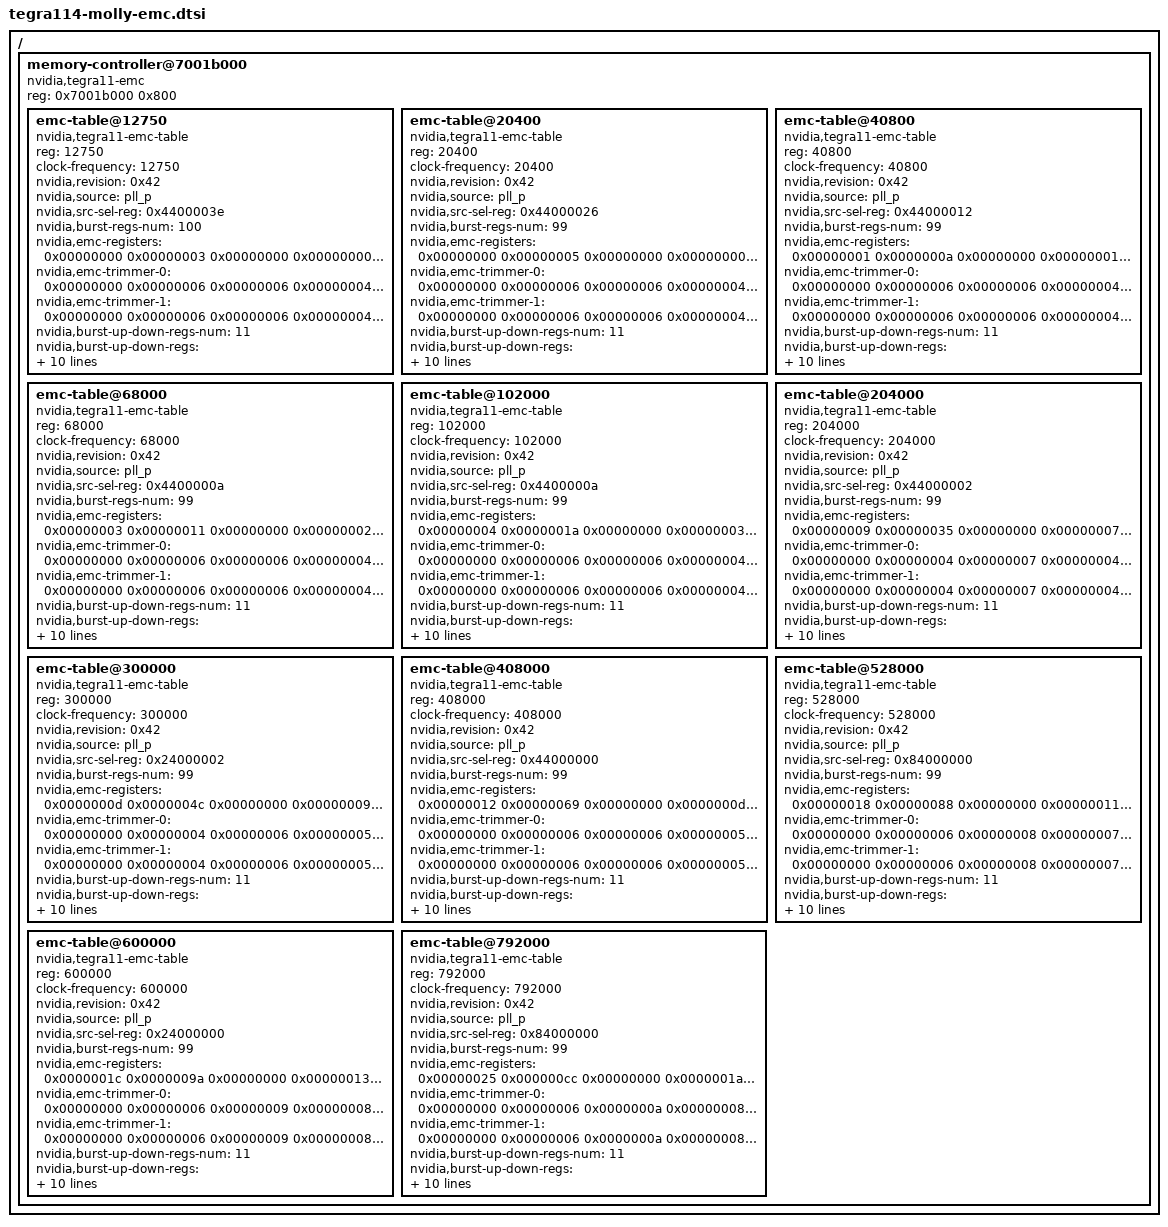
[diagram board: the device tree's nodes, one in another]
/ {
memory-controller@7001b000 {
	    compatible = "nvidia,tegra11-emc";
	    reg = <0x7001b000 0x800>;
	    #address-cells = <1>;
	    #size-cells = <0>;
	    emc-table@12750 {
		    reg = <12750>;
		    compatible = "nvidia,tegra11-emc-table";
		    clock-frequency = <12750>;
		    nvidia,revision = <0x42>;
		    nvidia,source = "pll_p";
		    nvidia,src-sel-reg = <0x4400003e>;
		    nvidia,burst-regs-num = <100>;
		    nvidia,emc-registers = <
			    0x00000000
			    0x00000003
			    0x00000000
			    0x00000000
		    	0x00000000
		    	0x00000004
		    	0x0000000a
		    	0x00000003
		    	0x0000000b
		    	0x00000000
		    	0x00000000
		    	0x00000003
		    	0x00000001
		    	0x00000000
		    	0x00000005
		    	0x0000000f
		    	0x00000006
		    	0x00010000
			    0x00000000
			    0x00000004
			    0x0000000f
			    0x00000060
			    0x00000000
			    0x00000018
			    0x00000002
			    0x00000002
		    	0x00000001
			    0x00000000
		    	0x00000007
		    	0x0000000f
			    0x00000005
			    0x00000005
			    0x00000004
			    0x00000004
			    0x00000004
		    	0x00000004
			    0x00000000
			    0x00000004
		    	0x00000005
		    	0x00000064
		    	0x00000005
		    	0x00000020
		    	0x00000000
		    	0x0000aa88
		    	0x002c00a0
		    	0x00008000
		    	0x00064000
		    	0x00064000
		    	0x00064000
			    0x00064000
			    0x00000000
		    	0x00000000
		    	0x00000000
			    0x00000000
			    0x00000000
			    0x00000000
			    0x00000000
			    0x00000000
		    	0x001112a0
		    	0x00000000
		    	0x0000a11c
			    0x00000000
                0x77ffc085
			    0x81f1f108
		    	0x03037504
			    0x0000003f
			    0x0000003f
			    0x00000007
			    0x02000000
			    0x00000802
			    0x00000000
			    0x00000042
			    0x000c000c
			    0x000c000c
			    0x00000000
			    0x00000000
			    0x00000000
			    0x00000000
			    0x800001c5
		    	0x1f7df7df
		    	0x0000001f
		    	0x40040001
		    	0x8000003f
		    	0x00000001
		    	0x00000001
			    0x00000002
			    0x00000000
			    0x00000001
			    0x00000001
			    0x00000002
			    0x00000008
			    0x00000002
			    0x00000001
			    0x00000003
			    0x00000006
		    	0x06030102
			    0x000a0402
			    0x77e30303
			    0x001f0000
		>;
		nvidia,emc-trimmer-0 = <
			0x00000000
			0x00000006
			0x00000006
			0x00000004
			0x00000004
			0x00064000
			0x00000009
			0x00000000
			0x0000000d
			0x00249249
			0x20820800
			0x0007c000
			0xa0f10f0f
			0x00000000
			0x00000a0a
			0x00000000
			0x00000000
			0x00000000
			0x00064000
			0x00064000
			0x00064000
			0x0007c000
			0x0007c000
			0x0007c000
			0x00000000
			0x00000000
			0x00000000
			0x00000000
			0x00000000
			0x00000000
		>;
		nvidia,emc-trimmer-1 = <
			0x00000000
			0x00000006
			0x00000006
			0x00000004
			0x00000004
			0x00064000
			0x00000009
			0x00000000
			0x0000000d
			0x00249249
			0x20820800
			0x0007c000
			0xa8f10f0f
			0x00000000
			0x00000b0b
			0x00000000
			0x00000000
			0x00000000
			0x00064000
			0x00064000
			0x00064000
			0x0007c000
			0x0007c000
			0x0007c000
			0x00000000
			0x00000000
			0x00000000
			0x00000000
			0x00000000
			0x00000000
		>;
		nvidia,burst-up-down-regs-num = <11>;
		nvidia,burst-up-down-regs = <
			0x00000007
			0x00ff00ff
			0x00ff00ff
			0x00ff00ff
			0x000000ff
			0x00ff00ff
			0x00ff00ff
			0x000000ff
			0x00ff00ff
			0x00ff00ff
			0x00ff00ff
		>;
		nvidia,emc-zcal-cnt-long = <0x00000042>;
		nvidia,emc-acal-interval = <0x001fffff>;
		nvidia,emc-mode-cfg = <0x7324000e>;
		nvidia,emc-mode-reset = <0x80001221>;
		nvidia,emc-mode-1 = <0x80100003>;
		nvidia,emc-mode-2 = <0x80200008>;
		nvidia,emc-mode-4 = <0x00000000>;
		nvidia,emc-min-mv = <900>;
		nvidia,emc-clock-latency-change = <57820>;
        };
	emc-table@20400 {
		reg = <20400>;
		compatible = "nvidia,tegra11-emc-table";
		clock-frequency = <20400>;
		nvidia,revision = <0x42>;
		nvidia,source = "pll_p";
		nvidia,src-sel-reg = <0x44000026>;
		nvidia,burst-regs-num = <99>;
		nvidia,emc-registers = <
			0x00000000
			0x00000005
			0x00000000
			0x00000000
			0x00000000
			0x00000004
			0x0000000a
			0x00000003
			0x0000000b
			0x00000000
			0x00000000
			0x00000003
			0x00000001
			0x00000000
			0x00000005
			0x0000000f
			0x00000006
			0x00010000
			0x00000000
			0x00000004
			0x0000000f
			0x0000009a
			0x00000000
			0x00000026
			0x00000002
			0x00000002
			0x00000001
			0x00000000
			0x00000007
			0x0000000f
			0x00000006
			0x00000006
			0x00000004
			0x00000004
			0x00000004
			0x00000004
			0x00000000
			0x00000004
			0x00000005
			0x000000a0
			0x00000005
			0x00000020
			0x00000000
			0x0000aa88
			0x002c00a0
			0x00008000
			0x00064000
			0x00064000
			0x00064000
			0x00064000
			0x00000000
			0x00000000
			0x00000000
			0x00000000
			0x00000000
			0x00000000
			0x00000000
			0x00000000
			0x001112a0
			0x00000000
			0x0000a11c
			0x00000000
			0x77ffc085
			0x81f1f108
			0x03037504
			0x0000003f
			0x0000003f
			0x0000000b
			0x02000000
			0x00000802
			0x00000000
			0x00000042
			0x000c000c
			0x000c000c
			0x00000000
			0x00000000
			0x00000000
			0x00000000
			0x8000023a
			0x1f7df7df
			0x0000001f
			0x40020001
			0x80000046
			0x00000001
			0x00000001
			0x00000002
			0x00000000
			0x00000001
			0x00000001
			0x00000002
			0x00000008
			0x00000002
			0x00000001
			0x00000003
			0x00000006
			0x06030102
			0x000a0402
			0x76230303
			0x001f0000
		>;
		nvidia,emc-trimmer-0 = <
			0x00000000
			0x00000006
			0x00000006
			0x00000004
			0x00000004
			0x00064000
			0x00000009
			0x00000000
			0x0000000d
			0x00249249
			0x20820800
			0x0007c000
			0xa0f10f0f
			0x00000000
			0x00000a0a
			0x00000000
			0x00000000
			0x00000000
			0x00064000
			0x00064000
			0x00064000
			0x0007c000
			0x0007c000
			0x0007c000
			0x00000000
			0x00000000
			0x00000000
			0x00000000
			0x00000000
			0x00000000
		>;
		nvidia,emc-trimmer-1 = <
			0x00000000
			0x00000006
			0x00000006
			0x00000004
			0x00000004
			0x00064000
			0x00000009
			0x00000000
			0x0000000d
			0x00249249
			0x20820800
			0x0007c000
			0xa8f10f0f
			0x00000000
			0x00000b0b
			0x00000000
			0x00000000
			0x00000000
			0x00064000
			0x00064000
			0x00064000
			0x0007c000
			0x0007c000
			0x0007c000
			0x00000000
			0x00000000
			0x00000000
			0x00000000
			0x00000000
			0x00000000
		>;
		nvidia,burst-up-down-regs-num = <11>;
		nvidia,burst-up-down-regs = <
			0x0000000a
			0x00ff00ff
			0x00ff00ff
			0x00ff00ff
			0x000000ff
			0x00ff00ff
			0x00ff00ff
			0x000000ff
			0x00ff00ff
			0x00ff00ff
			0x00ff00ff
		>;
		nvidia,emc-zcal-cnt-long = <0x00000042>;
		nvidia,emc-acal-interval = <0x001fffff>;
		nvidia,emc-mode-cfg = <0x7324000e>;
		nvidia,emc-mode-reset = <0x80001221>;
		nvidia,emc-mode-1 = <0x80100003>;
		nvidia,emc-mode-2 = <0x80200008>;
		nvidia,emc-mode-4 = <0x00000000>;
		nvidia,emc-min-mv = <900>;
		nvidia,emc-clock-latency-change = <35610>;
        };

	emc-table@40800 {
		reg = <40800>;
		compatible = "nvidia,tegra11-emc-table";
		clock-frequency = <40800>;
		nvidia,revision = <0x42>;
		nvidia,source = "pll_p";
		nvidia,src-sel-reg = <0x44000012>;
		nvidia,burst-regs-num = <99>;
		nvidia,emc-registers = <
			0x00000001
			0x0000000a
			0x00000000
			0x00000001
			0x00000000
			0x00000004
			0x0000000a
			0x00000003
			0x0000000b
			0x00000000
			0x00000000
			0x00000003
			0x00000001
			0x00000000
			0x00000005
			0x0000000f
			0x00000006
			0x00010000
			0x00000000
			0x00000004
			0x0000000f
			0x00000134
			0x00000000
			0x0000004d
			0x00000002
			0x00000002
			0x00000001
			0x00000000
			0x00000008
			0x0000000f
			0x0000000c
			0x0000000c
			0x00000004
			0x00000004
			0x00000004
			0x00000004
			0x00000000
			0x00000004
			0x00000005
			0x0000013f
			0x00000005
			0x00000020
			0x00000000
			0x0000aa88
			0x002c00a0
			0x00008000
			0x00064000
			0x00064000
			0x00064000
			0x00064000
			0x00000000
			0x00000000
			0x00000000
			0x00000000
			0x00000000
			0x00000000
			0x00000000
			0x00000000
			0x001112a0
			0x00000000
			0x0000a11c
			0x00000000
			0x77ffc085
			0x81f1f108
			0x03037504
			0x0000003f
			0x0000003f
			0x00000015
			0x02000000
			0x00000802
			0x00000000
			0x00000042
			0x000c000c
			0x000c000c
			0x00000000
			0x00000000
			0x00000000
			0x00000000
			0x80000370
			0x1f7df7df
			0x0000001f
			0xa0000001
			0x8000005b
			0x00000001
			0x00000001
			0x00000002
			0x00000000
			0x00000001
			0x00000001
			0x00000002
			0x00000008
			0x00000002
			0x00000001
			0x00000003
			0x00000006
			0x06030102
			0x000a0402
			0x74a30303
			0x001f0000
		>;
		nvidia,emc-trimmer-0 = <
			0x00000000
			0x00000006
			0x00000006
			0x00000004
			0x00000004
			0x00064000
			0x00000009
			0x00000000
			0x0000000d
			0x00249249
			0x20820800
			0x0007c000
			0xa0f10f0f
			0x00000000
			0x00000a0a
			0x00000000
			0x00000000
			0x00000000
			0x00064000
			0x00064000
			0x00064000
			0x0007c000
			0x0007c000
			0x0007c000
			0x00000000
			0x00000000
			0x00000000
			0x00000000
			0x00000000
			0x00000000
		>;
		nvidia,emc-trimmer-1 = <
			0x00000000
			0x00000006
			0x00000006
			0x00000004
			0x00000004
			0x00064000
			0x00000009
			0x00000000
			0x0000000d
			0x00249249
			0x20820800
			0x0007c000
			0xa8f10f0f
			0x00000000
			0x00000b0b
			0x00000000
			0x00000000
			0x00000000
			0x00064000
			0x00064000
			0x00064000
			0x0007c000
			0x0007c000
			0x0007c000
			0x00000000
			0x00000000
			0x00000000
			0x00000000
			0x00000000
			0x00000000
		>;
		nvidia,burst-up-down-regs-num = <11>;
		nvidia,burst-up-down-regs = <
			0x00000015
			0x00b000b0
			0x00b000c4
			0x00d700eb
			0x000000eb
			0x00eb00eb
			0x00ff00eb
			0x000000ff
			0x00ff00ff
			0x00ff00ff
			0x00ff00ff
		>;
		nvidia,emc-zcal-cnt-long = <0x00000042>;
		nvidia,emc-acal-interval = <0x001fffff>;
		nvidia,emc-mode-cfg = <0x7324000e>;
		nvidia,emc-mode-reset = <0x80001221>;
		nvidia,emc-mode-1 = <0x80100003>;
		nvidia,emc-mode-2 = <0x80200008>;
		nvidia,emc-mode-4 = <0x00000000>;
		nvidia,emc-min-mv = <900>;
		nvidia,emc-clock-latency-change = <20850>;
        };

	emc-table@68000 {
		reg = <68000>;
		compatible = "nvidia,tegra11-emc-table";
		clock-frequency = <68000>;
		nvidia,revision = <0x42>;
		nvidia,source = "pll_p";
		nvidia,src-sel-reg = <0x4400000a>;
		nvidia,burst-regs-num = <99>;
		nvidia,emc-registers = <
			0x00000003
			0x00000011
			0x00000000
			0x00000002
			0x00000000
			0x00000004
			0x0000000a
			0x00000003
			0x0000000b
			0x00000000
			0x00000000
			0x00000003
			0x00000001
			0x00000000
			0x00000005
			0x0000000f
			0x00000006
			0x00010000
			0x00000000
			0x00000004
			0x0000000f
			0x00000202
			0x00000000
			0x00000080
			0x00000002
			0x00000002
			0x00000001
			0x00000000
			0x0000000f
			0x0000000f
			0x00000013
			0x00000013
			0x00000004
			0x00000004
			0x00000004
			0x00000004
			0x00000000
			0x00000004
			0x00000005
			0x00000213
			0x00000005
			0x00000020
			0x00000000
			0x0000aa88
			0x002c00a0
			0x00008000
			0x00064000
			0x00064000
			0x00064000
			0x00064000
			0x00000000
			0x00000000
			0x00000000
			0x00000000
			0x00000000
			0x00000000
			0x00000000
			0x00000000
			0x001112a0
			0x00000000
			0x0000a11c
			0x00000000
			0x77ffc085
			0x81f1f108
			0x03037504
			0x0000003f
			0x0000003f
			0x00000022
			0x02000000
			0x00000802
			0x00000000
			0x00000042
			0x000c000c
			0x000c000c
			0x00000000
			0x00000000
			0x00000000
			0x00000000
			0x8000050e
			0x1f7df7df
			0x0000001f
			0x00000001
			0x80000076
			0x00000001
			0x00000001
			0x00000002
			0x00000000
			0x00000001
			0x00000001
			0x00000002
			0x00000008
			0x00000002
			0x00000001
			0x00000003
			0x00000006
			0x06030102
			0x000a0402
			0x74230403
			0x001f0000
		>;
		nvidia,emc-trimmer-0 = <
			0x00000000
			0x00000006
			0x00000006
			0x00000004
			0x00000004
			0x00064000
			0x00000009
			0x00000000
			0x0000000d
			0x00249249
			0x20820800
			0x0007c000
			0xa0f10f0f
			0x00008000
			0x00000a0a
			0x00000000
			0x00000000
			0x00008000
			0x00064000
			0x00064000
			0x00064000
			0x0007c000
			0x0007c000
			0x0007c000
			0x00000000
			0x00000000
			0x00000000
			0x00000000
			0x00000000
			0x00000000
		>;
		nvidia,emc-trimmer-1 = <
			0x00000000
			0x00000006
			0x00000006
			0x00000004
			0x00000004
			0x00064000
			0x00000009
			0x00000000
			0x0000000d
			0x00249249
			0x20820800
			0x0007c000
			0xa8f10f0f
			0x0000c000
			0x00000b0b
			0x00000000
			0x00000000
			0x0000c000
			0x00064000
			0x00064000
			0x00064000
			0x0007c000
			0x0007c000
			0x0007c000
			0x00000000
			0x00000000
			0x00000000
			0x00000000
			0x00000000
			0x00000000
		>;
		nvidia,burst-up-down-regs-num = <11>;
		nvidia,burst-up-down-regs = <
			0x00000023
			0x00690069
			0x00690075
			0x0081008d
			0x0000008d
			0x008d008d
			0x00bc008d
			0x000000bc
			0x00bc00bc
			0x00ff00ff
			0x00ff00ff
		>;
		nvidia,emc-zcal-cnt-long = <0x00000042>;
		nvidia,emc-acal-interval = <0x001fffff>;
		nvidia,emc-mode-cfg = <0x7324000e>;
		nvidia,emc-mode-reset = <0x80001221>;
		nvidia,emc-mode-1 = <0x80100003>;
		nvidia,emc-mode-2 = <0x80200008>;
		nvidia,emc-mode-4 = <0x00000000>;
		nvidia,emc-min-mv = <900>;
		nvidia,emc-clock-latency-change = <10720>;
        };

	emc-table@102000 {
		reg = <102000>;
		compatible = "nvidia,tegra11-emc-table";
		clock-frequency = <102000>;
		nvidia,revision = <0x42>;
		nvidia,source = "pll_p";
		nvidia,src-sel-reg = <0x4400000a>;
		nvidia,burst-regs-num = <99>;
		nvidia,emc-registers = <
			0x00000004
			0x0000001a
			0x00000000
			0x00000003
			0x00000001
			0x00000004
			0x0000000a
			0x00000003
			0x0000000b
			0x00000001
			0x00000001
			0x00000003
			0x00000001
			0x00000000
			0x00000005
			0x0000000f
			0x00000006
			0x00010000
			0x00000000
			0x00000004
			0x0000000f
			0x00000303
			0x00000000
			0x000000c0
			0x00000002
			0x00000002
			0x00000001
			0x00000000
			0x00000018
			0x0000000f
			0x0000001c
			0x0000001c
			0x00000004
			0x00000004
			0x00000004
			0x00000005
			0x00000000
			0x00000004
			0x00000005
			0x0000031c
			0x00000005
			0x00000020
			0x00000000
			0x0000aa88
			0x002c00a0
			0x00008000
			0x00064000
			0x00064000
			0x00064000
			0x00064000
			0x00000000
			0x00000000
			0x00000000
			0x00000000
			0x00000000
			0x00000000
			0x00000000
			0x00000000
			0x001112a0
			0x00000000
			0x0000a11c
			0x00000000
			0x77ffc085
			0x81f1f108
			0x03037504
			0x0000003f
			0x0000003f
			0x00000033
			0x02000000
			0x00000802
			0x00000000
			0x00000042
			0x000c000c
			0x000c000c
			0x00000000
			0x00000000
			0x00000000
			0x00000000
			0x80000713
			0x1f7df7df
			0x0000001f
			0x08000001
			0x80000098
			0x00000001
			0x00000001
			0x00000003
			0x00000000
			0x00000002
			0x00000001
			0x00000002
			0x00000008
			0x00000002
			0x00000001
			0x00000003
			0x00000006
			0x06030102
			0x000a0403
			0x73c30504
			0x001f0000
		>;
		nvidia,emc-trimmer-0 = <
			0x00000000
			0x00000006
			0x00000006
			0x00000004
			0x00000004
			0x00064000
			0x00000009
			0x00000000
			0x0000000d
			0x00249249
			0x20820800
			0x0007c000
			0xa0f10f0f
			0x00000000
			0x00000a0a
			0x00000000
			0x00000000
			0x00000000
			0x00064000
			0x00064000
			0x00064000
			0x0007c000
			0x0007c000
			0x0007c000
			0x00000000
			0x00000000
			0x00000000
			0x00000000
			0x00000000
			0x00000000
		>;
		nvidia,emc-trimmer-1 = <
			0x00000000
			0x00000006
			0x00000006
			0x00000004
			0x00000004
			0x00064000
			0x00000009
			0x00000000
			0x0000000d
			0x00249249
			0x20820800
			0x0007c000
			0xa8f10f0f
			0x00000000
			0x00000b0b
			0x00000000
			0x00000000
			0x00000000
			0x00064000
			0x00064000
			0x00064000
			0x0007c000
			0x0007c000
			0x0007c000
			0x00000000
			0x00000000
			0x00000000
			0x00000000
			0x00000000
			0x00000000
		>;
		nvidia,burst-up-down-regs-num = <11>;
		nvidia,burst-up-down-regs = <
			0x00000034
			0x00460046
			0x0046004e
			0x0056005e
			0x0000005e
			0x005e005e
			0x007d005e
			0x0000007d
			0x007d007d
			0x00ff00ff
			0x00ff00ff
		>;
		nvidia,emc-zcal-cnt-long = <0x00000042>;
		nvidia,emc-acal-interval = <0x001fffff>;
		nvidia,emc-mode-cfg = <0x7324000e>;
		nvidia,emc-mode-reset = <0x80001221>;
		nvidia,emc-mode-1 = <0x80100003>;
		nvidia,emc-mode-2 = <0x80200008>;
		nvidia,emc-mode-4 = <0x00000000>;
		nvidia,emc-min-mv = <900>;
		nvidia,emc-clock-latency-change = <6890>;
        };

	emc-table@204000 {
		reg = <204000>;
		compatible = "nvidia,tegra11-emc-table";
		clock-frequency = <204000>;
		nvidia,revision = <0x42>;
		nvidia,source = "pll_p";
		nvidia,src-sel-reg = <0x44000002>;
		nvidia,burst-regs-num = <99>;
		nvidia,emc-registers = <
			0x00000009
			0x00000035
			0x00000000
			0x00000007
			0x00000002
			0x00000004
			0x0000000a
			0x00000003
			0x0000000b
			0x00000002
			0x00000002
			0x00000003
			0x00000001
			0x00000000
			0x00000005
			0x0000000f
			0x00000006
			0x00010000
			0x00000000
			0x00000004
			0x0000000f
			0x00000607
			0x00000000
			0x00000181
			0x00000002
			0x00000002
			0x00000001
			0x00000000
			0x00000032
			0x0000000f
			0x00000038
			0x00000038
			0x00000004
			0x00000004
			0x00000004
			0x00000009
			0x00000000
			0x00000004
			0x00000005
			0x00000638
			0x00000006
			0x00000020
			0x00000000
			0x0000aa88
			0x002c00a0
			0x00008000
			0x00064000
			0x00064000
			0x00064000
			0x00064000
			0x00000000
			0x00000000
			0x00000000
			0x00000000
			0x00000000
			0x00000000
			0x00000000
			0x00000000
			0x001112a0
			0x00000000
			0x0000a11c
			0x00000000
			0x77ffc085
			0x81f1f108
			0x03037504
			0x0000003f
			0x0000003f
			0x00000000
			0x02000000
			0x00000802
			0x00020000
			0x00000100
			0x000c000c
			0x000c000c
			0x00000000
			0x00000000
			0x00000000
			0x00000000
			0x80000d22
			0x1f7df7df
			0x0000001f
			0x01000003
			0x800000fe
			0x00000001
			0x00000001
			0x00000005
			0x00000002
			0x00000004
			0x00000001
			0x00000002
			0x00000008
			0x00000002
			0x00000001
			0x00000003
			0x00000006
			0x06030102
			0x000a0405
			0x73840a06
			0x001f0000
		>;
		nvidia,emc-trimmer-0 = <
			0x00000000
			0x00000004
			0x00000007
			0x00000004
			0x00000004
			0x00064000
			0x00000009
			0x00000000
			0x0000000d
			0x00249249
			0x20820800
			0x0007c000
			0xa0f10f0f
			0x00000000
			0x00000a0a
			0x00000000
			0x00000000
			0x00000000
			0x00064000
			0x00064000
			0x00064000
			0x0007c000
			0x0007c000
			0x0007c000
			0x00000000
			0x00000000
			0x00000000
			0x00000000
			0x00000000
			0x00000000
		>;
		nvidia,emc-trimmer-1 = <
			0x00000000
			0x00000004
			0x00000007
			0x00000004
			0x00000004
			0x00064000
			0x00000009
			0x00000000
			0x0000000d
			0x00249249
			0x20820800
			0x0007c000
			0xa8f10f0f
			0x00000000
			0x00000b0b
			0x00000000
			0x00000000
			0x00000000
			0x00064000
			0x00064000
			0x00064000
			0x0007c000
			0x0007c000
			0x0007c000
			0x00000000
			0x00000000
			0x00000000
			0x00000000
			0x00000000
			0x00000000
		>;
		nvidia,burst-up-down-regs-num = <11>;
		nvidia,burst-up-down-regs = <
			0x00000068
			0x00230023
			0x00230027
			0x002b002f
			0x0000002f
			0x002f002f
			0x003e002f
			0x0000003e
			0x003e003e
			0x00ff00c8
			0x00ff00ff
		>;
		nvidia,emc-zcal-cnt-long = <0x00000042>;
		nvidia,emc-acal-interval = <0x001fffff>;
		nvidia,emc-mode-cfg = <0x7320000e>;
		nvidia,emc-mode-reset = <0x80001221>;
		nvidia,emc-mode-1 = <0x80100003>;
		nvidia,emc-mode-2 = <0x80200008>;
		nvidia,emc-mode-4 = <0x00000000>;
		nvidia,emc-min-mv = <900>;
		nvidia,emc-clock-latency-change = <3420>;
        };

	emc-table@300000 {
		reg = <300000>;
		compatible = "nvidia,tegra11-emc-table";
		clock-frequency = <300000>;
		nvidia,revision = <0x42>;
		nvidia,source = "pll_p";
		nvidia,src-sel-reg = <0x24000002>;
		nvidia,burst-regs-num = <99>;
		nvidia,emc-registers = <
			0x0000000d
			0x0000004c
			0x00000000
			0x00000009
			0x00000003
			0x00000004
			0x00000008
			0x00000002
			0x00000009
			0x00000003
			0x00000003
			0x00000002
			0x00000001
			0x00000000
			0x00000004
			0x0000000f
			0x00000006
			0x00010000
			0x00000000
			0x00000004
			0x0000000f
			0x000008e4
			0x00000000
			0x00000239
			0x00000001
			0x00000008
			0x00000001
			0x00000000
			0x0000004a
			0x0000000e
			0x00000051
			0x00000200
			0x00000004
			0x00000004
			0x00000004
			0x0000000c
			0x00000000
			0x00000004
			0x00000005
			0x00000924
			0x00000000
			0x00000020
			0x00000000
			0x00005088
			0x002c00a0
			0x00008000
			0x00030000
			0x00030000
			0x00030000
			0x00030000
			0x00000000
			0x00000000
			0x00000000
			0x00000000
			0x00000000
			0x00000000
			0x00000000
			0x00000000
			0x001112a0
			0x00000000
			0x0001013d
			0x00000000
			0x77ffc085
			0x81f1f108
			0x03037504
			0x00000000
			0x0000003f
			0x00000000
			0x02000000
			0x00000802
			0x00020000
			0x00000100
			0x0174000c
			0x0174000c
			0x00000000
			0x00000000
			0x00000000
			0x00000000
			0x800012d7
			0x1f7df7df
			0x0000001f
			0x08000004
			0x8000015e
			0x00000001
			0x00000002
			0x00000007
			0x00000004
			0x00000005
			0x00000001
			0x00000002
			0x00000007
			0x00000002
			0x00000002
			0x00000004
			0x00000006
			0x06040202
			0x000b0607
			0x77450e08
			0x001f0000
		>;
		nvidia,emc-trimmer-0 = <
			0x00000000
			0x00000004
			0x00000006
			0x00000005
			0x00000004
			0x00030000
			0x0000000b
			0x00000000
			0x0000000d
			0x00249249
			0x20820800
			0x00044000
			0xa0f10f0f
			0x00014000
			0x00000909
			0x00000000
			0x00000000
			0x00014000
			0x00030000
			0x00030000
			0x00030000
			0x00044000
			0x00044000
			0x00044000
			0x00000000
			0x00000000
			0x00000000
			0x00000000
			0x00000000
			0x00000000
		>;
		nvidia,emc-trimmer-1 = <
			0x00000000
			0x00000004
			0x00000006
			0x00000005
			0x00000004
			0x00030000
			0x0000000b
			0x00000000
			0x0000000d
			0x00249249
			0x20820800
			0x00044000
			0xa8f10f0f
			0x00014000
			0x00000909
			0x00000000
			0x00000000
			0x00014000
			0x00030000
			0x00030000
			0x00030000
			0x00044000
			0x00044000
			0x00044000
			0x00000000
			0x00000000
			0x00000000
			0x00000000
			0x00000000
			0x00000000
		>;
		nvidia,burst-up-down-regs-num = <11>;
		nvidia,burst-up-down-regs = <
			0x0000009a
			0x00180018
			0x0018001a
			0x001d0020
			0x00000020
			0x00200020
			0x002a0020
			0x0000002a
			0x002a002a
			0x00ff0088
			0x00ff00ff
		>;
		nvidia,emc-zcal-cnt-long = <0x00000042>;
		nvidia,emc-acal-interval = <0x001fffff>;
		nvidia,emc-mode-cfg = <0x5300000e>;
		nvidia,emc-mode-reset = <0x80000321>;
		nvidia,emc-mode-1 = <0x80100002>;
		nvidia,emc-mode-2 = <0x80200000>;
		nvidia,emc-mode-4 = <0x00000000>;
		nvidia,emc-min-mv = <900>;
		nvidia,emc-clock-latency-change = <2450>;
        };

	emc-table@408000 {
		reg = <408000>;
		compatible = "nvidia,tegra11-emc-table";
		clock-frequency = <408000>;
		nvidia,revision = <0x42>;
		nvidia,source = "pll_p";
		nvidia,src-sel-reg = <0x44000000>;
		nvidia,burst-regs-num = <99>;
		nvidia,emc-registers = <
			0x00000012
			0x00000069
			0x00000000
			0x0000000d
			0x00000004
			0x00000005
			0x00000009
			0x00000002
			0x0000000c
			0x00000004
			0x00000004
			0x00000002
			0x00000001
			0x00000000
			0x00000004
			0x0000000f
			0x00000006
			0x00010000
			0x00000000
			0x00000004
			0x00000010
			0x00000c2e
			0x00000000
			0x0000030b
			0x00000001
			0x00000008
			0x00000001
			0x00000000
			0x00000066
			0x00000011
			0x0000006f
			0x00000200
			0x00000004
			0x00000004
			0x00000004
			0x00000011
			0x00000000
			0x00000004
			0x00000005
			0x00000c6f
			0x00000000
			0x00000020
			0x00000000
			0x00005088
			0x002c0080
			0x00008000
			0x00028000
			0x00028000
			0x00028000
			0x00028000
			0x00000000
			0x00000000
			0x00000000
			0x00000000
			0x00000000
			0x00000000
			0x00000000
			0x00000000
			0x001112a0
			0x00000000
			0x0001013d
			0x00000000
			0x77ffc085
			0x81f1f108
			0x03037504
			0x00000000
			0x0000003f
			0x00000000
			0x02000000
			0x00000802
			0x00020000
			0x00000100
			0x0158000c
			0x0158000c
			0x00000000
			0x00000000
			0x00000000
			0x00000000
			0x80001941
			0x1f7df7df
			0x0000001f
			0x02000006
			0x80000190
			0x00000001
			0x00000002
			0x0000000a
			0x00000006
			0x00000008
			0x00000001
			0x00000002
			0x00000009
			0x00000002
			0x00000002
			0x00000004
			0x00000006
			0x06040202
			0x000e070a
			0x7547130b
			0x001f0000
		>;
		nvidia,emc-trimmer-0 = <
			0x00000000
			0x00000006
			0x00000006
			0x00000005
			0x00000004
			0x00028000
			0x0000000c
			0x00000000
			0x0000000e
			0x00249249
			0x20820800
			0x00030000
			0xa0f10f0f
			0x00004000
			0x00000808
			0x00000000
			0x00000000
			0x00004000
			0x00028000
			0x00028000
			0x00028000
			0x00030000
			0x00030000
			0x00030000
			0x00000000
			0x00000000
			0x00000000
			0x00000000
			0x00000000
			0x00000000
		>;
		nvidia,emc-trimmer-1 = <
			0x00000000
			0x00000006
			0x00000006
			0x00000005
			0x00000004
			0x00028000
			0x0000000c
			0x00000000
			0x0000000e
			0x00249249
			0x20820800
			0x00030000
			0xa8f10f0f
			0x00004000
			0x00000909
			0x00000000
			0x00000000
			0x00004000
			0x00028000
			0x00028000
			0x00028000
			0x00030000
			0x00030000
			0x00030000
			0x00000000
			0x00000000
			0x00000000
			0x00000000
			0x00000000
			0x00000000
		>;
		nvidia,burst-up-down-regs-num = <11>;
		nvidia,burst-up-down-regs = <
			0x000000d1
			0x00110011
			0x00110013
			0x00150017
			0x00000017
			0x00170017
			0x001f0017
			0x0000001f
			0x001f001f
			0x00d30064
			0x00d300d3
		>;
		nvidia,emc-zcal-cnt-long = <0x00000042>;
		nvidia,emc-acal-interval = <0x001fffff>;
		nvidia,emc-mode-cfg = <0x53000006>;
		nvidia,emc-mode-reset = <0x80000731>;
		nvidia,emc-mode-1 = <0x80100002>;
		nvidia,emc-mode-2 = <0x80200008>;
		nvidia,emc-mode-4 = <0x00000000>;
		nvidia,emc-min-mv = <900>;
		nvidia,emc-clock-latency-change = <1750>;
        };

	emc-table@528000 {
		reg = <528000>;
		compatible = "nvidia,tegra11-emc-table";
		clock-frequency = <528000>;
		nvidia,revision = <0x42>;
		nvidia,source = "pll_p";
		nvidia,src-sel-reg = <0x84000000>;
		nvidia,burst-regs-num = <99>;
		nvidia,emc-registers = <
			0x00000018
			0x00000088
			0x00000000
			0x00000011
			0x00000006
			0x00000006
			0x00000009
			0x00000002
			0x0000000d
			0x00000006
			0x00000006
			0x00000002
			0x00000001
			0x00000000
			0x00000005
			0x0000000f
			0x00000009
			0x00010000
			0x00000000
			0x00000006
			0x00000012
			0x00000fd6
			0x00000000
			0x000003f5
			0x00000002
			0x0000000b
			0x00000001
			0x00000000
			0x00000084
			0x00000012
			0x0000008f
			0x00000200
			0x00000004
			0x00000004
			0x00000004
			0x00000016
			0x00000000
			0x00000005
			0x00000006
			0x00001017
			0x00000000
			0x00000020
			0x00000000
			0x00005088
			0xf0120091
			0x00008000
			0x0000000a
			0x0000000a
			0x0000000a
			0x0000000a
			0x00000000
			0x00000000
			0x00000000
			0x00000000
			0x00000000
			0x00000000
			0x00000000
			0x00000000
			0x001112a0
			0x00000000
			0x0000013d
			0x00000000
			0x77ffc085
			0x81f1f108
			0x07077504
			0x00000000
			0x0000003f
			0x00000000
			0x02000000
			0x00000802
			0x00020000
			0x00000100
			0x013a000c
			0x013a000c
			0x00000000
			0x00000000
			0x00000000
			0x00000000
			0x80002062
			0x1f7df7df
			0x0000001f
			0x0f000007
			0x80000190
			0x00000002
			0x00000003
			0x0000000d
			0x00000008
			0x0000000a
			0x00000001
			0x00000002
			0x00000009
			0x00000002
			0x00000002
			0x00000005
			0x00000006
			0x06050202
			0x0010090d
			0x7428180e
			0x001f0000
		>;
		nvidia,emc-trimmer-0 = <
			0x00000000
			0x00000006
			0x00000008
			0x00000007
			0x00000004
			0x0000000a
			0x0000000c
			0x00000000
			0x00000010
			0x00249249
			0x20820800
			0x0000000b
			0xa0f10f0f
			0x00000000
			0x00000909
			0x00000000
			0x00000000
			0x00000000
			0x0000000a
			0x0000000a
			0x0000000a
			0x0000000b
			0x0000000b
			0x0000000b
			0x00000000
			0x00000000
			0x00000000
			0x00000000
			0x00000000
			0x00000000
		>;
		nvidia,emc-trimmer-1 = <
			0x00000000
			0x00000006
			0x00000008
			0x00000007
			0x00000004
			0x0000000a
			0x0000000c
			0x00000000
			0x00000010
			0x00249249
			0x20820800
			0x0000000b
			0xa8f10f0f
			0x00000000
			0x00000909
			0x00000000
			0x00000000
			0x00000000
			0x0000000a
			0x0000000a
			0x0000000a
			0x0000000b
			0x0000000b
			0x0000000b
			0x00000000
			0x00000000
			0x00000000
			0x00000000
			0x00000000
			0x00000000
		>;
		nvidia,burst-up-down-regs-num = <11>;
		nvidia,burst-up-down-regs = <
			0x0000010e
			0x000d000d
			0x000d000f
			0x00100012
			0x00000012
			0x00120012
			0x00180012
			0x00000018
			0x00180018
			0x00a3004d
			0x00a300a3
		>;
		nvidia,emc-zcal-cnt-long = <0x00000042>;
		nvidia,emc-acal-interval = <0x001fffff>;
		nvidia,emc-mode-cfg = <0x53000004>;
		nvidia,emc-mode-reset = <0x80000941>;
		nvidia,emc-mode-1 = <0x80100002>;
		nvidia,emc-mode-2 = <0x80200008>;
		nvidia,emc-mode-4 = <0x00000000>;
		nvidia,emc-min-mv = <900>;
		nvidia,emc-clock-latency-change = <1440>;
        };

	emc-table@600000 {
		reg = <600000>;
		compatible = "nvidia,tegra11-emc-table";
		clock-frequency = <600000>;
		nvidia,revision = <0x42>;
		nvidia,source = "pll_p";
		nvidia,src-sel-reg = <0x24000000>;
		nvidia,burst-regs-num = <99>;
		nvidia,emc-registers = <
			0x0000001c
			0x0000009a
			0x00000000
			0x00000013
			0x00000007
			0x00000007
			0x0000000b
			0x00000003
			0x00000010
			0x00000007
			0x00000007
			0x00000002
			0x00000001
			0x00000000
			0x00000005
			0x0000000f
			0x0000000a
			0x00010000
			0x00000000
			0x00000007
			0x00000014
			0x00001208
			0x00000000
			0x00000482
			0x00000002
			0x0000000d
			0x00000001
			0x00000000
			0x00000096
			0x00000015
			0x000000a2
			0x00000200
			0x00000004
			0x00000004
			0x00000004
			0x00000018
			0x00000000
			0x00000005
			0x00000006
			0x00001248
			0x00000009
			0x00000020
			0x00000000
			0x0000ba88
			0xf00e0191
			0x00008000
			0x0000000a
			0x0000000a
			0x0000000a
			0x0000000a
			0x00000000
			0x00000000
			0x00000000
			0x00000000
			0x00000000
			0x00000000
			0x00000000
			0x00000000
			0x001112a0
			0x00000000
			0x0000013d
			0x00000000
			0x77ffc085
			0x81f1f108
			0x07077504
			0x00000000
			0x0000003f
			0x00000000
			0x02000000
			0x00000802
			0x00020000
			0x00000100
			0x0128000c
			0x0128000c
			0x00000000
			0x00000000
			0x00000000
			0x00000000
			0x800024aa
			0x1f7df7df
			0x0000001f
			0x00000009
			0x80000190
			0x00000003
			0x00000004
			0x0000000e
			0x00000009
			0x0000000b
			0x00000001
			0x00000003
			0x0000000b
			0x00000002
			0x00000002
			0x00000005
			0x00000007
			0x07050202
			0x00130b0e
			0x73a91b0f
			0x001f0000
		>;
		nvidia,emc-trimmer-0 = <
			0x00000000
			0x00000006
			0x00000009
			0x00000008
			0x00000004
			0x0000000a
			0x0000000c
			0x00000000
			0x00000012
			0x00249249
			0x20820800
			0x0000000a
			0xa0f10f0f
			0x00000000
			0x00000909
			0x00000000
			0x00000000
			0x00000000
			0x0000000a
			0x0000000a
			0x0000000a
			0x0000000a
			0x0000000a
			0x0000000a
			0x00000000
			0x00000000
			0x00000000
			0x00000000
			0x00000000
			0x00000000
		>;
		nvidia,emc-trimmer-1 = <
			0x00000000
			0x00000006
			0x00000009
			0x00000008
			0x00000004
			0x0000000a
			0x0000000c
			0x00000000
			0x00000012
			0x00249249
			0x20820800
			0x0000000a
			0xa8f10f0f
			0x00000000
			0x00000909
			0x00000000
			0x00000000
			0x00000000
			0x0000000a
			0x0000000a
			0x0000000a
			0x0000000a
			0x0000000a
			0x0000000a
			0x00000000
			0x00000000
			0x00000000
			0x00000000
			0x00000000
			0x00000000
		>;
		nvidia,burst-up-down-regs-num = <11>;
		nvidia,burst-up-down-regs = <
			0x00000133
			0x000c000c
			0x000c000d
			0x000e0010
			0x00000010
			0x00100010
			0x00150010
			0x00000015
			0x00150015
			0x00900044
			0x00900090
		>;
		nvidia,emc-zcal-cnt-long = <0x00000042>;
		nvidia,emc-acal-interval = <0x001fffff>;
		nvidia,emc-mode-cfg = <0x53200000>;
		nvidia,emc-mode-reset = <0x80000b61>;
		nvidia,emc-mode-1 = <0x80100002>;
		nvidia,emc-mode-2 = <0x80200010>;
		nvidia,emc-mode-4 = <0x00000000>;
		nvidia,emc-min-mv = <900>;
		nvidia,emc-clock-latency-change = <1300>;
        };

	emc-table@792000 {
		reg = <792000>;
		compatible = "nvidia,tegra11-emc-table";
		clock-frequency = <792000>;
		nvidia,revision = <0x42>;
		nvidia,source = "pll_p";
		nvidia,src-sel-reg = <0x84000000>;
		nvidia,burst-regs-num = <99>;
		nvidia,emc-registers = <
			0x00000025
			0x000000cc
			0x00000000
			0x0000001a
			0x00000009
			0x00000008
			0x0000000d
			0x00000004
			0x00000013
			0x00000009
			0x00000009
			0x00000003
			0x00000001
			0x00000000
			0x00000006
			0x0000000f
			0x0000000b
			0x00010000
			0x00000000
			0x00000008
			0x00000016
			0x000017e1
			0x00000000
			0x000005f8
			0x00000003
			0x00000011
			0x00000001
			0x00000000
			0x000000c6
			0x00000018
			0x000000d6
			0x00000200
			0x00000005
			0x00000005
			0x00000005
			0x00000020
			0x00000000
			0x00000007
			0x00000008
			0x00001822
			0x00000000
			0x80000000
			0x00000000
			0x00005088
			0xf0070191
			0x00008000
			0x00000008
			0x00000008
			0x00000008
			0x00000008
			0x00000000
			0x00000000
			0x00000000
			0x00000000
			0x00000000
			0x00000000
			0x00000000
			0x00000000
			0x001112a0
			0x00000000
			0x0000013d
			0x00000000
			0x77ffc085
			0x81f1f108
			0x07077504
			0x00000000
			0x0000003f
			0x00000000
			0x02000000
			0x00000802
			0x00020000
			0x00000100
			0x00f8000c
			0x00f8000c
			0x00000000
			0x00000000
			0x00000000
			0x00000000
			0x80003012
			0x1f7df7df
			0x0000001f
			0x0e00000b
			0x80000190
			0x00000004
			0x00000005
			0x00000013
			0x0000000c
			0x0000000f
			0x00000002
			0x00000003
			0x0000000c
			0x00000002
			0x00000002
			0x00000006
			0x00000008
			0x08060202
			0x00160d13
			0x734c2414
			0x001f0000
		>;
		nvidia,emc-trimmer-0 = <
			0x00000000
			0x00000006
			0x0000000a
			0x00000008
			0x00000006
			0x00000008
			0x0000000d
			0x00000000
			0x00000014
			0x0028a28a
			0x20820800
			0x0000000b
			0xa0f10f0f
			0x00004000
			0x00000a0a
			0x00000000
			0x00000000
			0x00004000
			0x00000008
			0x00000008
			0x00000008
			0x0000000b
			0x0000000b
			0x0000000b
			0x00000000
			0x00000000
			0x00000000
			0x00000000
			0x00000000
			0x00000000
		>;
		nvidia,emc-trimmer-1 = <
			0x00000000
			0x00000006
			0x0000000a
			0x00000008
			0x00000006
			0x00000008
			0x0000000d
			0x00000000
			0x00000014
			0x0028a28a
			0x20820800
			0x0000000b
			0xa8f10f0f
			0x00004000
			0x00000b0b
			0x00000000
			0x00000000
			0x00004000
			0x00000008
			0x00000008
			0x00000008
			0x0000000b
			0x0000000b
			0x0000000b
			0x00000000
			0x00000000
			0x00000000
			0x00000000
			0x00000000
			0x00000000
		>;
		nvidia,burst-up-down-regs-num = <11>;
		nvidia,burst-up-down-regs = <
			0x00000196
			0x00090009
			0x0009000a
			0x000b000c
			0x0000000c
			0x000c000c
			0x0010000c
			0x00000010
			0x00100010
			0x006d0033
			0x006d006d
		>;
		nvidia,emc-zcal-cnt-long = <0x00000042>;
		nvidia,emc-acal-interval = <0x001fffff>;
		nvidia,emc-mode-cfg = <0x53000000>;
		nvidia,emc-mode-reset = <0x80000d71>;
		nvidia,emc-mode-1 = <0x80100002>;
		nvidia,emc-mode-2 = <0x80200418>;
		nvidia,emc-mode-4 = <0x00000000>;
		nvidia,emc-min-mv = <900>;
		nvidia,emc-clock-latency-change = <1200>;
        };
	};
};
